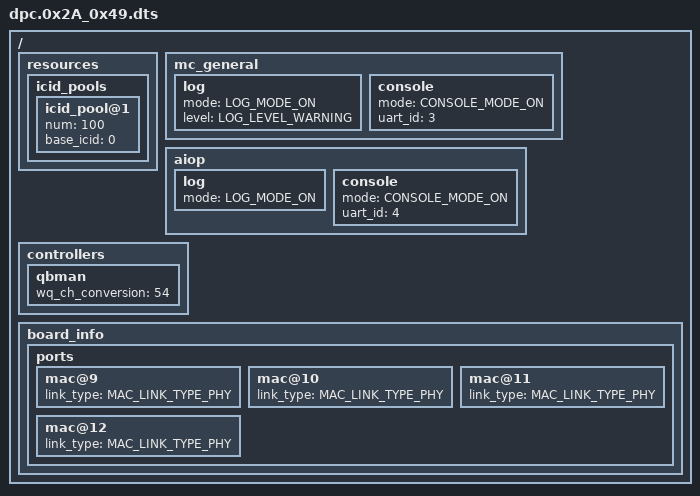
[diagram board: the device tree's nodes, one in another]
/*
 * This DPC showcases one Linux configuration for SerDes 0x2a_49, maximizing
 * resources allotted to the Ethernet driver. This is by no means a necessity,
 * the DPAA2 Linux Eth driver can work with fewer resources, albeit with lesser
 * performance.
 *
 * Copyright 2016 Freescale Semiconductor, Inc.
 */

/dts-v1/;
/* DPC */
/ {
	resources {
		icid_pools {
			icid_pool@1 {
				num = <100>;
				base_icid = <0>;
			};
		};
	};
	mc_general {
		log {
			mode = "LOG_MODE_ON";
			level = "LOG_LEVEL_WARNING";
		};
		console {
			mode = "CONSOLE_MODE_ON";
			uart_id = <3>;
		};
	};
	aiop {
		log {
			mode = "LOG_MODE_ON";
		};
		console {
			mode = "CONSOLE_MODE_ON";
			uart_id = <4>;
		};
	};
	controllers {
		qbman {
			/* Transform this number of 8-WQ channels into four times
			 * as many 2-WQ channels. This allows the creation of a
			 * larger number of DPCONs.
			 */
			wq_ch_conversion = <54>;
		};
	};
	board_info {
		ports {
			/* For QDS SerDes 0x2a_49: 4 SGMII ports. */
			mac@9 {
				link_type = "MAC_LINK_TYPE_PHY";
			};
			mac@10 {
				link_type = "MAC_LINK_TYPE_PHY";
			};
			mac@11 {
				link_type = "MAC_LINK_TYPE_PHY";
			};
			mac@12 {
				link_type = "MAC_LINK_TYPE_PHY";
			};
		};
	};
};
